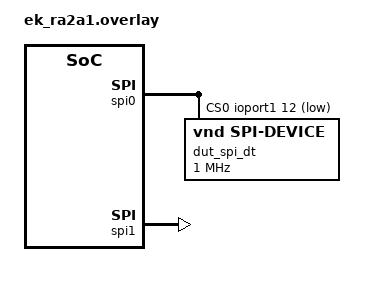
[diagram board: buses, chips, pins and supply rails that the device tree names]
/*
 * Copyright (c) 2025 Renesas Electronics Corporation
 * SPDX-License-Identifier: Apache-2.0
 */

&pinctrl {
	spi0_default_alt: spi0_default_alt {
		group1 {
			/* MISO MOSI RSPCK */
			psels = <RA_PSEL(RA_PSEL_SPI, 3, 4)>,
				<RA_PSEL(RA_PSEL_SPI, 3, 3)>,
				<RA_PSEL(RA_PSEL_SPI, 1, 11)>;
		};
	};

	spi1_default_alt: spi1_default_alt {
		group1 {
			/* MISO MOSI RSPCK */
			psels = <RA_PSEL(RA_PSEL_SPI, 2, 5)>,
				<RA_PSEL(RA_PSEL_SPI, 2, 4)>,
				<RA_PSEL(RA_PSEL_SPI, 1, 3)>;
		};
	};
};

&spi0 {
	rx-dtc;
	tx-dtc;
	status = "okay";
	pinctrl-0 = <&spi0_default_alt>;
	pinctrl-names = "default";
	cs-gpios = <&ioport1 12 GPIO_ACTIVE_LOW>;
	interrupts = <24 1>, <25 1>, <26 1>, <27 1>;
	interrupt-names = "rxi", "txi", "tei", "eri";

	dut_spi_dt: test-spi-dev@0 {
		compatible = "vnd,spi-device";
		reg = <0>;
		spi-max-frequency = <1000000>;
	};
};

dut_spis: &spi1 {
	rx-dtc;
	tx-dtc;
	status = "okay";
	pinctrl-0 = <&spi1_default_alt>;
	pinctrl-names = "default";
	cs-gpios = <&ioport2 6 GPIO_ACTIVE_LOW>;
};
